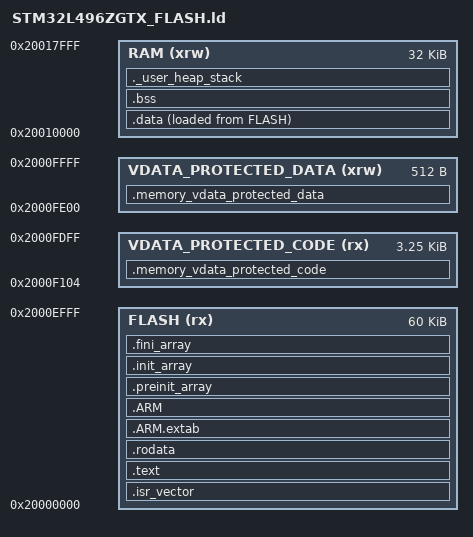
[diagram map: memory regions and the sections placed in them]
/*
******************************************************************************
**
** @file        : LinkerScript.ld
**
** @author      : Auto-generated by STM32CubeIDE
**
**  Abstract    : Linker script for NUCLEO-L496ZG Board embedding STM32L496ZGTx Device from stm32l4 series
**                      1024Kbytes ROM
**                      256Kbytes RAM
**                      64Kbytes SRAM2
**
**                Set heap size, stack size and stack location according
**                to application requirements.
**
**                Set memory bank area and size if external memory is used
**
**  Target      : STMicroelectronics STM32
**
**  Distribution: The file is distributed as is, without any warranty
**                of any kind.
**
******************************************************************************
** @attention
**
** Copyright (c) 2022 STMicroelectronics.
** All rights reserved.
**
** This software is licensed under terms that can be found in the LICENSE file
** in the root directory of this software component.
** If no LICENSE file comes with this software, it is provided AS-IS.
**
******************************************************************************
*/

/* Entry Point */
ENTRY(Reset_Handler)

/* Highest address of the user mode stack */
_estack = ORIGIN(RAM) + LENGTH(RAM); /* end of "RAM" Ram type memory */
/* Generate a link error if heap and stack don't fit into RAM */
_Min_Heap_Size = 0x0;      /* required amount of heap  */
_Min_Stack_Size = 0x400; /* required amount of stack */

/* Specify the memory areas */
/*
** Note! MEMORY_B1 is only needed if system requires some code/data to be 
** placed at special memory location. MEMORY_B1 specification can be removed if 
** not needed. In that case also remove MEMORY_B1 section at the end of this 
** file. Additional memory sections can also be added here.   
*/
MEMORY
{
RAM (xrw)      : ORIGIN = 0x20010000, LENGTH = 32K
FLASH (rx)      : ORIGIN = 0x20000000, LENGTH = 60K
/****************************************************************************/
/*                                                                          */
/*   VDATA_PROTECTED_CODE: used to locate code in protected code segment    */
/*                                                                          */
/****************************************************************************/
/* Note that the protected code segment doesn't exactly start at the 
   starting address used to configure de Firewall.
   This allows to locate the function used to open the Firewall at the
   correct address to obey the call gate sequence */
  VDATA_PROTECTED_CODE (rx)   : ORIGIN = 0x2000F104, LENGTH = 3324
/***************************************************************************/
/*                                                                         */
/*    VDATA_PROTECTED_DATA: used to locate data in volatile data segment   */
/*                                                                         */
/***************************************************************************/        
  VDATA_PROTECTED_DATA (xrw)  : ORIGIN = 0x2000FE00, LENGTH = 512
}

/* Define output sections */
SECTIONS
{
  /* The startup code goes first into FLASH */
  .isr_vector :
  {
    . = ALIGN(8);
    KEEP(*(.isr_vector)) /* Startup code */
    . = ALIGN(8);
  } >FLASH

  /* The program code and other data goes into FLASH */
  .text :
  {
    . = ALIGN(8);
    *(.text)           /* .text sections (code) */
    *(.text*)          /* .text* sections (code) */
    *(.glue_7)         /* glue arm to thumb code */
    *(.glue_7t)        /* glue thumb to arm code */
    *(.eh_frame)

    KEEP (*(.init))
    KEEP (*(.fini))

    . = ALIGN(8);
    _etext = .;        /* define a global symbols at end of code */
  } >FLASH

  /* Constant data goes into FLASH */
  .rodata :
  {
    . = ALIGN(8);
    *(.rodata)         /* .rodata sections (constants, strings, etc.) */
    *(.rodata*)        /* .rodata* sections (constants, strings, etc.) */
    . = ALIGN(8);
  } >FLASH

  .ARM.extab   : 
  { 
  . = ALIGN(8);
  *(.ARM.extab* .gnu.linkonce.armextab.*)
  . = ALIGN(8);
  } >FLASH
  .ARM : {
	. = ALIGN(8);
    __exidx_start = .;
    *(.ARM.exidx*)
    __exidx_end = .;
	. = ALIGN(8);
  } >FLASH

  .preinit_array     :
  {
	. = ALIGN(8);
    PROVIDE_HIDDEN (__preinit_array_start = .);
    KEEP (*(.preinit_array*))
    PROVIDE_HIDDEN (__preinit_array_end = .);
	. = ALIGN(8);
  } >FLASH
  
  .init_array :
  {
	. = ALIGN(8);
    PROVIDE_HIDDEN (__init_array_start = .);
    KEEP (*(SORT(.init_array.*)))
    KEEP (*(.init_array*))
    PROVIDE_HIDDEN (__init_array_end = .);
	. = ALIGN(8);
  } >FLASH
  .fini_array :
  {
	. = ALIGN(8);
    PROVIDE_HIDDEN (__fini_array_start = .);
    KEEP (*(SORT(.fini_array.*)))
    KEEP (*(.fini_array*))
    PROVIDE_HIDDEN (__fini_array_end = .);
	. = ALIGN(8);
  } >FLASH

  /* used by the startup to initialize data */
  _sidata = LOADADDR(.data);

  /* Initialized data sections goes into RAM, load LMA copy after code */
  .data : 
  {
    . = ALIGN(8);
    _sdata = .;        /* create a global symbol at data start */
    *(.data)           /* .data sections */
    *(.data*)          /* .data* sections */

    . = ALIGN(8);
    _edata = .;        /* define a global symbol at data end */
  } >RAM AT> FLASH

  
  /* Uninitialized data section */
  . = ALIGN(4);
  .bss :
  {
    /* This is used by the startup in order to initialize the .bss secion */
    _sbss = .;         /* define a global symbol at bss start */
    __bss_start__ = _sbss;
    *(.bss)
    *(.bss*)
    *(COMMON)

    . = ALIGN(4);
    _ebss = .;         /* define a global symbol at bss end */
    __bss_end__ = _ebss;
  } >RAM

  /* User_heap_stack section, used to check that there is enough RAM left */
  ._user_heap_stack :
  {
    . = ALIGN(8);
    PROVIDE ( end = . );
    PROVIDE ( _end = . );
    . = . + _Min_Heap_Size;
    . = . + _Min_Stack_Size;
    . = ALIGN(8);
  } >RAM

  /*************************************************************************/   
  /*                                                                       */
  /* VDATA_PROTECTED_CODE section, code is located here explicitly         */
  /* refer to protected_vdata_code.c:                                      */
  /*                                                                       */    
  /* uint32_t __attribute__((section(".vdata_protected_code"))) vdata_protected_function(uint32_t * array) */
  /*                                                                       */
  /*************************************************************************/      
  .memory_vdata_protected_code :
  {
    *(.vdata_protected_code)        /* .vdata_protected_code sections (code) */
    *(.vdata_protected_code*)       /* .vdata_protected_code* sections (code)  */
  } >VDATA_PROTECTED_CODE


  /*************************************************************************/   
  /*                                                                       */
  /* VDATA_PROTECTED_DATA section, data is located here explicitly         */
  /* refer to protected_volatile_data.c:                                   */
  /* uint32_t __attribute__((section(".vdata_protected_data")))  protected_volatile_array[N] = {50, 51, 52, 53, 54, 55, 56, 57, 58, 59}; */
  /*                                                                       */
  /*************************************************************************/      
  .memory_vdata_protected_data :
  {
    *(.vdata_protected_data)        /* .vdata_protected_data sections (code) */
    *(.vdata_protected_data*)       /* .vdata_protected_data* sections (code)  */
  } >VDATA_PROTECTED_DATA


  /* Remove information from the standard libraries */
  /DISCARD/ :
  {
    libc.a ( * )
    libm.a ( * )
    libgcc.a ( * )
  }

  .ARM.attributes 0 : { *(.ARM.attributes) }
}
